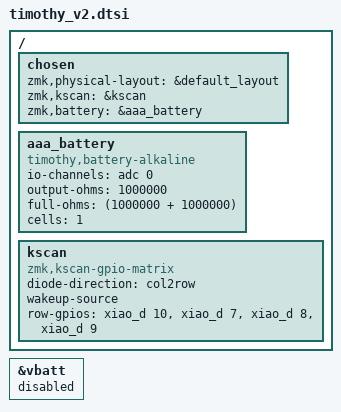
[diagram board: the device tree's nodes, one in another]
// 左右の基板 (キーと電池がある側) 共通の設定。ドングルはこのファイルを読み込まない。

#include "timothy_v2-layouts.dtsi"

/ {
    chosen {
        zmk,physical-layout = &default_layout;
        zmk,kscan = &kscan;
        zmk,battery = &aaa_battery;
    };

    // 単4アルカリ乾電池 1 本の電圧を 1MΩ + 1MΩ で半分に分圧して D0 (P0.02 = AIN0) に入力し、残量を測る。
    //   電池+ --[1MΩ]--+-- D0 --[1MΩ]-- GND
    aaa_battery: aaa_battery {
        compatible = "timothy,battery-alkaline";
        io-channels = <&adc 0>;
        output-ohms = <1000000>;            // D0 - GND 間の抵抗
        full-ohms = <(1000000 + 1000000)>;  // 分圧抵抗の合計
        cells = <1>;
    };

    kscan: kscan {
        compatible = "zmk,kscan-gpio-matrix";
        diode-direction = "col2row";
        wakeup-source;

        row-gpios
            = <&xiao_d 10 (GPIO_ACTIVE_HIGH | GPIO_PULL_DOWN)>  // row-0: D10
            , <&xiao_d 7  (GPIO_ACTIVE_HIGH | GPIO_PULL_DOWN)>  // row-1: D7
            , <&xiao_d 8  (GPIO_ACTIVE_HIGH | GPIO_PULL_DOWN)>  // row-2: D8
            , <&xiao_d 9  (GPIO_ACTIVE_HIGH | GPIO_PULL_DOWN)>  // row-3: D9
            ;
    };
};

// XIAO 内蔵のリチウムイオン用電圧測定 (P0.31) は使わないので無効化する。
&vbatt {
    status = "disabled";
};
